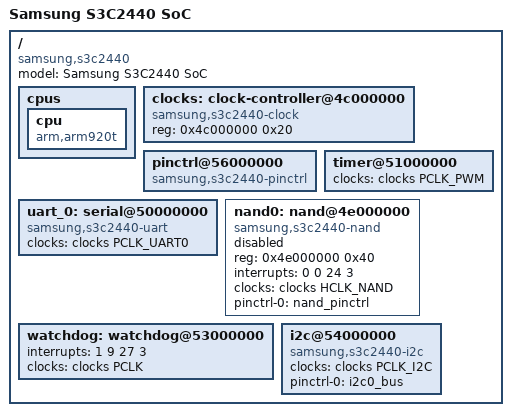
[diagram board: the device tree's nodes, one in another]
// SPDX-License-Identifier: GPL-2.0
/*
 * Samsung's s3c2440 SoC device tree source
 *
 * Copyright (c) 2013 Heiko Stuebner <heiko@sntech.de>
 */

#include "/home/zhoubo/desktop/Linux内核移植/tq2440/linux-4.19-rc3/include/dt-bindings/clock/s3c2410.h"
#include "s3c24xx.dtsi"
#include "s3c2440-pinctrl.dtsi"

/ {
	model = "Samsung S3C2440 SoC";
	compatible = "samsung,s3c2440";
/*
	aliases {
		serial3 = &uart_3;
	};
*/
	cpus {
		#address-cells = <1>;
		#size-cells = <0>;
		cpu {
			compatible = "arm,arm920t";
		};
	};
	// for tq2440
/*
	interrupt-controller@4a000000 {
		compatible = "samsung,s3c2440-irq";
	};
*/	
	clocks: clock-controller@4c000000 {
		compatible = "samsung,s3c2440-clock";
		reg = <0x4c000000 0x20>;
		#clock-cells = <1>;
	};

	pinctrl@56000000 {
		compatible = "samsung,s3c2440-pinctrl";
	};

	timer@51000000 {
		clocks = <&clocks PCLK_PWM>;
		clock-names = "timers";
	};

	uart_0: serial@50000000 {
		compatible = "samsung,s3c2440-uart";
		clock-names = "uart";
//		"clk_uart_baud2";
		//"clk_uart_baud3";
		clocks = <&clocks PCLK_UART0>; // <&clocks PCLK_UART0>;
	};
			
	nand0: nand@4e000000 {
		compatible = "samsung,s3c2440-nand";
		reg = <0x4e000000 0x40>;
		interrupts = <0 0 24 3>;
		clocks = <&clocks HCLK_NAND>;
		clock-names = "nand";
		pinctrl-names = "default";
		pinctrl-0 = <&nand_pinctrl>;
		status = "disabled";													};

/*
	uart_1: serial@50004000 {
		compatible = "samsung,s3c2440-uart";
		clock-names = "uart", "clk_uart_baud2",
				"clk_uart_baud3";
		clocks = <&clocks PCLK_UART1>, <&clocks PCLK_UART1>,
				<&clocks SCLK_UART>;
	};

	uart_2: serial@50008000 {
		compatible = "samsung,s3c2440-uart";
		clock-names = "uart", "clk_uart_baud2",
				"clk_uart_baud3";
		clocks = <&clocks PCLK_UART2>, <&clocks PCLK_UART2>,
				<&clocks SCLK_UART>;
	};

	uart_3: serial@5000c000 {
		compatible = "samsung,s3c2440-uart";
		reg = <0x5000C000 0x4000>;
		interrupts = <1 18 24 4>, <1 18 25 4>;
		clock-names = "uart", "clk_uart_baud2",
				"clk_uart_baud3";
		clocks = <&clocks PCLK_UART3>, <&clocks PCLK_UART3>,
				<&clocks SCLK_UART>;
		status = "disabled";
	};

	sdhci_1: sdhci@4ac00000 {
		compatible = "samsung,s3c6410-sdhci";
		reg = <0x4AC00000 0x100>;
		interrupts = <0 0 21 3>;
		clock-names = "hsmmc", "mmc_busclk.0",
				"mmc_busclk.2";
		clocks = <&clocks HCLK_HSMMC0>, <&clocks HCLK_HSMMC0>,
				<&clocks MUX_HSMMC0>;
		status = "disabled";
	};
	sdhci_0: sdhci@4a800000 {
		compatible = "samsung,s3c6410-sdhci";
		reg = <0x4A800000 0x100>;
		interrupts = <0 0 20 3>;
		clock-names = "hsmmc", "mmc_busclk.0",
				"mmc_busclk.2";
		clocks = <&clocks HCLK_HSMMC1>, <&clocks HCLK_HSMMC1>,
				<&clocks MUX_HSMMC1>;
		status = "disabled";
	};
*/
	watchdog: watchdog@53000000 {
		interrupts = <1 9 27 3>;
		clocks = <&clocks PCLK>;
		clock-names = "watchdog";
	};
/*
	rtc: rtc@57000000 {
	//	compatible = "samsung,s3c2440-rtc";
		clocks = <&clocks PCLK_RTC>;
		clock-names = "rtc";
	};
*/
	i2c@54000000 {
		compatible = "samsung,s3c2440-i2c";
		clocks = <&clocks PCLK_I2C>;
		clock-names = "i2c";
		pinctrl-names = "default";
		pinctrl-0 = <&i2c0_bus>;
	};
};
